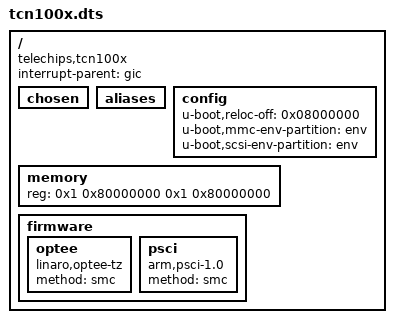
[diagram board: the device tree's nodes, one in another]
// SPDX-License-Identifier: (GPL-2.0-or-later OR MIT)
/*
 * Copyright (C) 2023 Telechips Inc.
 */

/ {
	compatible = "telechips,tcn100x";
	interrupt-parent = <&gic>;
	#address-cells = <2>;
	#size-cells = <2>;

	chosen: chosen {};
	aliases: aliases {};

	config: config {
		u-boot,reloc-off = <0x08000000>;
		u-boot,mmc-env-partition = "env";
		u-boot,scsi-env-partition = "env";
	};

	memory: memory {
		device_type = "memory";
		reg = <0x1 0x80000000 0x1 0x80000000>;
	};

	firmware: firmware {
		optee: optee {
			compatible = "linaro,optee-tz";
			method = "smc";
		};

		psci: psci {
			compatible = "arm,psci-1.0";
			method = "smc";
		};
	};
};

#include "tcn100x-cpu.dtsi"
#include "tcn100x-clk.dtsi"
#include "tcn100x-gpio.dtsi"
#include "tcn100x-uart.dtsi"
#include "tcn100x-mmc.dtsi"
#include "tcn100x-i2c.dtsi"
#include "tcn100x-pwm.dtsi"
#include "tcn100x-adc.dtsi"
#include "tcn100x-spi.dtsi"
#include "tcn100x-usb.dtsi"
